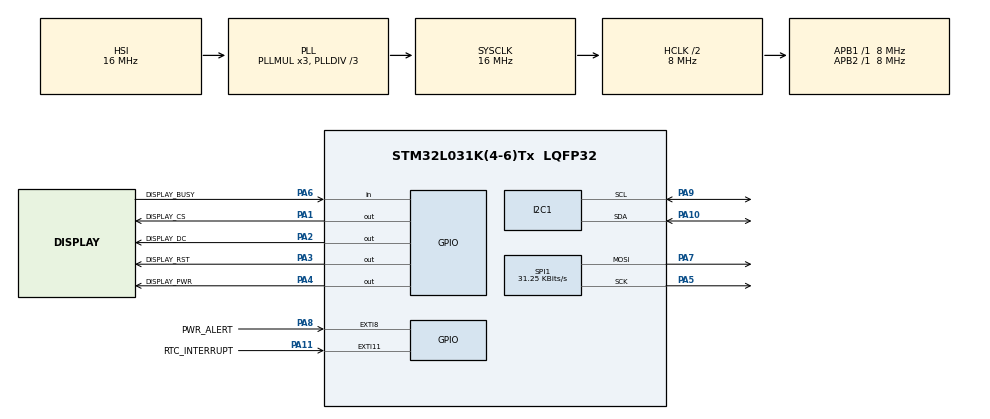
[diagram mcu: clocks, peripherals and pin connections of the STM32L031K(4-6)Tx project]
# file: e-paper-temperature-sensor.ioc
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I2C1.Timing=0x2000090E
Mcu.Family=STM32L0
Mcu.Name=STM32L031K(4-6)Tx
Mcu.Package=LQFP32
NVIC.EXTI4_15_IRQn=true\:3\:0\:true\:false\:true\:true\:true\:true
NVIC.TIM21_IRQn=true\:2\:0\:true\:false\:true\:true\:true\:true
PA1.GPIO_Label=DISPLAY_CS
PA1.Signal=GPIO_Output
PA10.Mode=I2C
PA10.Signal=I2C1_SDA
PA11.GPIO_Label=RTC_INTERRUPT
PA11.Signal=GPXTI11
PA13.Mode=Serial_Wire
PA13.Signal=SYS_SWDIO
PA14.Mode=Serial_Wire
PA14.Signal=SYS_SWCLK
PA2.GPIO_Label=DISPLAY_DC
PA2.Signal=GPIO_Output
PA3.GPIO_Label=DISPLAY_RST
PA3.GPIO_ModeDefaultOutputPP=GPIO_MODE_OUTPUT_PP
PA3.GPIO_PuPd=GPIO_NOPULL
PA3.PinState=GPIO_PIN_SET
PA3.Signal=GPIO_Output
PA4.GPIO_Label=DISPLAY_PWR
PA4.PinState=GPIO_PIN_SET
PA4.Signal=GPIO_Output
PA5.Mode=TX_Only_Simplex_Unidirect_Master
PA5.Signal=SPI1_SCK
PA6.GPIO_Label=DISPLAY_BUSY
PA6.Signal=GPIO_Input
PA7.Mode=TX_Only_Simplex_Unidirect_Master
PA7.Signal=SPI1_MOSI
PA8.GPIO_Label=PWR_ALERT
PA8.Signal=GPXTI8
PA9.Mode=I2C
PA9.Signal=I2C1_SCL
ProjectManager.HeapSize=0x200
ProjectManager.StackSize=0x400
ProjectManager.TargetToolchain=Makefile
RCC.AHBCLKDivider=RCC_SYSCLK_DIV2
RCC.AHBFreq_Value=8000000
RCC.APB1Freq_Value=8000000
RCC.APB1TimFreq_Value=8000000
RCC.APB2Freq_Value=8000000
RCC.APB2TimFreq_Value=8000000
RCC.HCLKFreq_Value=8000000
RCC.HSE_VALUE=8000000
RCC.HSI16_VALUE=16000000
RCC.HSI_VALUE=16000000
RCC.LSE_VALUE=32768
RCC.MSI_VALUE=2097000
RCC.PLLDIV=RCC_PLLDIV_3
RCC.SYSCLKFreq_VALUE=16000000
RCC.SYSCLKSource=RCC_SYSCLKSOURCE_PLLCLK
RCC.VCOOutputFreq_Value=48000000
SPI1.BaudRatePrescaler=SPI_BAUDRATEPRESCALER_256
SPI1.CLKPolarity=SPI_POLARITY_LOW
SPI1.CRCCalculation=SPI_CRCCALCULATION_DISABLE
SPI1.CalculateBaudRate=31.25 KBits/s
SPI1.Direction=SPI_DIRECTION_2LINES
SPI1.Mode=SPI_MODE_MASTER
SPI1.VirtualType=VM_MASTER
TIM21.Period=1000
TIM21.Prescaler=8*1024-1
VP_TIM21_VS_OPM.Mode=OPM_bit
board=custom

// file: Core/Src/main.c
/* USER CODE BEGIN Header */
/**
 ******************************************************************************
 * @file           : main.c
 * @brief          : Main program body
 ******************************************************************************
 * @attention
 *
 * Copyright (c) 2024 STMicroelectronics.
 * All rights reserved.
 *
 * This software is licensed under terms that can be found in the LICENSE file
 * in the root directory of this software component.
 * If no LICENSE file comes with this software, it is provided AS-IS.
 *
 ******************************************************************************
 */
/* USER CODE END Header */
#include "main.h"

/* USER CODE BEGIN Includes */
#include "er_epm027.h"
#include "gui.h"
#include "sht40.h"
/* USER CODE END Includes */

I2C_HandleTypeDef hi2c1;

SPI_HandleTypeDef hspi1;

TIM_HandleTypeDef htim21;

void SystemClock_Config(void);
static void MX_GPIO_Init(void);
static void MX_I2C1_Init(void);
static void MX_SPI1_Init(void);
static void MX_TIM21_Init(void);

int main(void)
{

  /* MCU Configuration--------------------------------------------------------*/

  /* Reset of all peripherals, Initializes the Flash interface and the Systick. */
  HAL_Init();

  /* Configure the system clock */
  SystemClock_Config();

  /* Initialize all configured peripherals */
  MX_GPIO_Init();
  MX_I2C1_Init();
  MX_SPI1_Init();
  MX_TIM21_Init();
  /* USER CODE BEGIN 2 */

    SHT40_init(&hi2c1);
    ER_EPM027_init(&hspi1);
    ER_EPM027_clearScreen();

    GUI_init();

    HAL_TIM_Base_Start_IT(&htim21);
    HAL_SuspendTick();
    HAL_PWR_EnableSleepOnExit();
    HAL_PWR_EnterSLEEPMode(PWR_MAINREGULATOR_ON, PWR_SLEEPENTRY_WFI);

  /* USER CODE END 2 */

  /* Infinite loop */
    while (1) {

    /* USER CODE BEGIN 3 */

        // HAL_Delay(1000);
    }
  /* USER CODE END 3 */
}

void SystemClock_Config(void)
{
  RCC_OscInitTypeDef RCC_OscInitStruct = {0};
  RCC_ClkInitTypeDef RCC_ClkInitStruct = {0};
  RCC_PeriphCLKInitTypeDef PeriphClkInit = {0};

  /** Configure the main internal regulator output voltage
  */
  __HAL_PWR_VOLTAGESCALING_CONFIG(PWR_REGULATOR_VOLTAGE_SCALE1);

  /** Initializes the RCC Oscillators according to the specified parameters
  * in the RCC_OscInitTypeDef structure.
  */
  RCC_OscInitStruct.OscillatorType = RCC_OSCILLATORTYPE_HSI;
  RCC_OscInitStruct.HSIState = RCC_HSI_ON;
  RCC_OscInitStruct.HSICalibrationValue = RCC_HSICALIBRATION_DEFAULT;
  RCC_OscInitStruct.PLL.PLLState = RCC_PLL_ON;
  RCC_OscInitStruct.PLL.PLLSource = RCC_PLLSOURCE_HSI;
  RCC_OscInitStruct.PLL.PLLMUL = RCC_PLLMUL_3;
  RCC_OscInitStruct.PLL.PLLDIV = RCC_PLLDIV_3;
  if (HAL_RCC_OscConfig(&RCC_OscInitStruct) != HAL_OK)
  {
    Error_Handler();
  }

  /** Initializes the CPU, AHB and APB buses clocks
  */
  RCC_ClkInitStruct.ClockType = RCC_CLOCKTYPE_HCLK|RCC_CLOCKTYPE_SYSCLK
                              |RCC_CLOCKTYPE_PCLK1|RCC_CLOCKTYPE_PCLK2;
  RCC_ClkInitStruct.SYSCLKSource = RCC_SYSCLKSOURCE_PLLCLK;
  RCC_ClkInitStruct.AHBCLKDivider = RCC_SYSCLK_DIV2;
  RCC_ClkInitStruct.APB1CLKDivider = RCC_HCLK_DIV1;
  RCC_ClkInitStruct.APB2CLKDivider = RCC_HCLK_DIV1;

  if (HAL_RCC_ClockConfig(&RCC_ClkInitStruct, FLASH_LATENCY_0) != HAL_OK)
  {
    Error_Handler();
  }
  PeriphClkInit.PeriphClockSelection = RCC_PERIPHCLK_I2C1;
  PeriphClkInit.I2c1ClockSelection = RCC_I2C1CLKSOURCE_PCLK1;
  if (HAL_RCCEx_PeriphCLKConfig(&PeriphClkInit) != HAL_OK)
  {
    Error_Handler();
  }
}

static void MX_I2C1_Init(void)
{

  hi2c1.Instance = I2C1;
  hi2c1.Init.Timing = 0x2000090E;
  hi2c1.Init.OwnAddress1 = 0;
  hi2c1.Init.AddressingMode = I2C_ADDRESSINGMODE_7BIT;
  hi2c1.Init.DualAddressMode = I2C_DUALADDRESS_DISABLE;
  hi2c1.Init.OwnAddress2 = 0;
  hi2c1.Init.OwnAddress2Masks = I2C_OA2_NOMASK;
  hi2c1.Init.GeneralCallMode = I2C_GENERALCALL_DISABLE;
  hi2c1.Init.NoStretchMode = I2C_NOSTRETCH_DISABLE;
  if (HAL_I2C_Init(&hi2c1) != HAL_OK)
  {
    Error_Handler();
  }

  /** Configure Analogue filter
  */
  if (HAL_I2CEx_ConfigAnalogFilter(&hi2c1, I2C_ANALOGFILTER_ENABLE) != HAL_OK)
  {
    Error_Handler();
  }

  /** Configure Digital filter
  */
  if (HAL_I2CEx_ConfigDigitalFilter(&hi2c1, 0) != HAL_OK)
  {
    Error_Handler();
  }

}

static void MX_SPI1_Init(void)
{

  /* SPI1 parameter configuration*/
  hspi1.Instance = SPI1;
  hspi1.Init.Mode = SPI_MODE_MASTER;
  hspi1.Init.Direction = SPI_DIRECTION_2LINES;
  hspi1.Init.DataSize = SPI_DATASIZE_8BIT;
  hspi1.Init.CLKPolarity = SPI_POLARITY_LOW;
  hspi1.Init.CLKPhase = SPI_PHASE_1EDGE;
  hspi1.Init.NSS = SPI_NSS_SOFT;
  hspi1.Init.BaudRatePrescaler = SPI_BAUDRATEPRESCALER_256;
  hspi1.Init.FirstBit = SPI_FIRSTBIT_MSB;
  hspi1.Init.TIMode = SPI_TIMODE_DISABLE;
  hspi1.Init.CRCCalculation = SPI_CRCCALCULATION_DISABLE;
  hspi1.Init.CRCPolynomial = 7;
  if (HAL_SPI_Init(&hspi1) != HAL_OK)
  {
    Error_Handler();
  }

}

static void MX_TIM21_Init(void)
{

  TIM_MasterConfigTypeDef sMasterConfig = {0};

  htim21.Instance = TIM21;
  htim21.Init.Prescaler = 8*1024-1;
  htim21.Init.CounterMode = TIM_COUNTERMODE_UP;
  htim21.Init.Period = 1000;
  htim21.Init.ClockDivision = TIM_CLOCKDIVISION_DIV1;
  htim21.Init.AutoReloadPreload = TIM_AUTORELOAD_PRELOAD_DISABLE;
  if (HAL_TIM_OnePulse_Init(&htim21, TIM_OPMODE_SINGLE) != HAL_OK)
  {
    Error_Handler();
  }
  sMasterConfig.MasterOutputTrigger = TIM_TRGO_RESET;
  sMasterConfig.MasterSlaveMode = TIM_MASTERSLAVEMODE_DISABLE;
  if (HAL_TIMEx_MasterConfigSynchronization(&htim21, &sMasterConfig) != HAL_OK)
  {
    Error_Handler();
  }

}

static void MX_GPIO_Init(void)
{
  GPIO_InitTypeDef GPIO_InitStruct = {0};

  /* GPIO Ports Clock Enable */
  __HAL_RCC_GPIOA_CLK_ENABLE();

  /*Configure GPIO pin Output Level */
  HAL_GPIO_WritePin(GPIOA, DISPLAY_CS_Pin|DISPLAY_DC_Pin, GPIO_PIN_RESET);

  /*Configure GPIO pin Output Level */
  HAL_GPIO_WritePin(GPIOA, DISPLAY_RST_Pin|DISPLAY_PWR_Pin, GPIO_PIN_SET);

  /*Configure GPIO pins : DISPLAY_CS_Pin DISPLAY_DC_Pin DISPLAY_RST_Pin DISPLAY_PWR_Pin */
  GPIO_InitStruct.Pin = DISPLAY_CS_Pin|DISPLAY_DC_Pin|DISPLAY_RST_Pin|DISPLAY_PWR_Pin;
  GPIO_InitStruct.Mode = GPIO_MODE_OUTPUT_PP;
  GPIO_InitStruct.Pull = GPIO_NOPULL;
  GPIO_InitStruct.Speed = GPIO_SPEED_FREQ_LOW;
  HAL_GPIO_Init(GPIOA, &GPIO_InitStruct);

  /*Configure GPIO pin : DISPLAY_BUSY_Pin */
  GPIO_InitStruct.Pin = DISPLAY_BUSY_Pin;
  GPIO_InitStruct.Mode = GPIO_MODE_INPUT;
  GPIO_InitStruct.Pull = GPIO_NOPULL;
  HAL_GPIO_Init(DISPLAY_BUSY_GPIO_Port, &GPIO_InitStruct);

  /*Configure GPIO pins : PWR_ALERT_Pin RTC_INTERRUPT_Pin */
  GPIO_InitStruct.Pin = PWR_ALERT_Pin|RTC_INTERRUPT_Pin;
  GPIO_InitStruct.Mode = GPIO_MODE_IT_RISING;
  GPIO_InitStruct.Pull = GPIO_NOPULL;
  HAL_GPIO_Init(GPIOA, &GPIO_InitStruct);

  /* EXTI interrupt init*/
  HAL_NVIC_SetPriority(EXTI4_15_IRQn, 3, 0);
  HAL_NVIC_EnableIRQ(EXTI4_15_IRQn);

}

void Error_Handler(void)
{
    __disable_irq();
    while (1) {
    }
}
